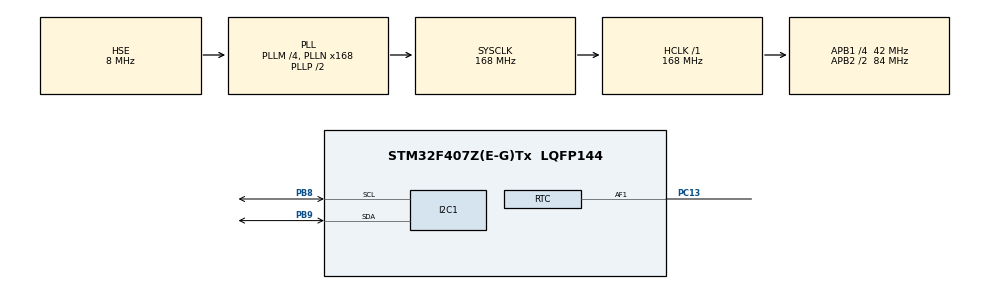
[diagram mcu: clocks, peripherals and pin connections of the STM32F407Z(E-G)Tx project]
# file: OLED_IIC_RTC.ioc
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Mcu.Family=STM32F4
Mcu.Name=STM32F407Z(E-G)Tx
Mcu.Package=LQFP144
NVIC.PriorityGroup=NVIC_PRIORITYGROUP_2
NVIC.RTC_Alarm_IRQn=true\:1\:1\:true\:false\:true\:true\:true\:true
NVIC.RTC_WKUP_IRQn=true\:1\:0\:true\:false\:true\:true\:true\:true
PA13.Mode=Serial_Wire
PA13.Signal=SYS_JTMS-SWDIO
PA14.Mode=Serial_Wire
PA14.Signal=SYS_JTCK-SWCLK
PB8.Mode=I2C
PB8.Signal=I2C1_SCL
PB9.Mode=I2C
PB9.Signal=I2C1_SDA
PC13-ANTI_TAMP.Mode=WakeUpAF1
PC13-ANTI_TAMP.Signal=RTC_AF1
PC14-OSC32_IN.Mode=LSE-External-Oscillator
PC14-OSC32_IN.Signal=RCC_OSC32_IN
PC15-OSC32_OUT.Mode=LSE-External-Oscillator
PC15-OSC32_OUT.Signal=RCC_OSC32_OUT
PH0-OSC_IN.Mode=HSE-External-Oscillator
PH0-OSC_IN.Signal=RCC_OSC_IN
PH1-OSC_OUT.Mode=HSE-External-Oscillator
PH1-OSC_OUT.Signal=RCC_OSC_OUT
ProjectManager.HeapSize=0x200
ProjectManager.StackSize=0x400
ProjectManager.TargetToolchain=STM32CubeIDE
RCC.48MHZClocksFreq_Value=84000000
RCC.AHBFreq_Value=168000000
RCC.APB1CLKDivider=RCC_HCLK_DIV4
RCC.APB1Freq_Value=42000000
RCC.APB1TimFreq_Value=84000000
RCC.APB2CLKDivider=RCC_HCLK_DIV2
RCC.APB2Freq_Value=84000000
RCC.APB2TimFreq_Value=168000000
RCC.CortexFreq_Value=168000000
RCC.HCLKFreq_Value=168000000
RCC.HSE_VALUE=8000000
RCC.HSI_VALUE=16000000
RCC.PLLM=4
RCC.PLLN=168
RCC.PLLSourceVirtual=RCC_PLLSOURCE_HSE
RCC.RCC_RTC_Clock_Source=RCC_RTCCLKSOURCE_LSE
RCC.SYSCLKFreq_VALUE=168000000
RCC.SYSCLKSource=RCC_SYSCLKSOURCE_PLLCLK
RCC.VCOOutputFreq_Value=336000000
RTC.Alarm=RTC_ALARM_A
RTC.AlarmDateWeekDay=3
RTC.AlarmMaskDateWeekDay=RTC_ALARMMASK_DATEWEEKDAY
RTC.AlarmMaskDateWeekDay_B=RTC_ALARMMASK_DATEWEEKDAY
RTC.AlarmMaskHours=RTC_ALARMMASK_HOURS
RTC.AlarmMaskHours_B=RTC_ALARMMASK_HOURS
RTC.AlarmMaskMinutes_B=RTC_ALARMMASK_MINUTES
RTC.Alarm_B=RTC_ALARM_B
RTC.Date=16
RTC.Hours=7
RTC.Hours_A=8
RTC.Hours_B=10
RTC.Minutes=15
RTC.Minutes_A=16
RTC.Minutes_B=20
RTC.Month=RTC_MONTH_MARCH
RTC.OutPutPolarity=RTC_OUTPUT_POLARITY_LOW
RTC.Seconds=10
RTC.Seconds_A=5
RTC.Seconds_B=30
RTC.WakeUpClock=RTC_WAKEUPCLOCK_CK_SPRE_16BITS
RTC.WeekDay=RTC_WEEKDAY_SATURDAY
RTC.Year=19
VP_RTC_VS_RTC_Activate.Mode=RTC_Enabled
VP_RTC_VS_RTC_Alarm_A_Intern.Mode=Alarm A
VP_RTC_VS_RTC_Alarm_B_Intern.Mode=Alarm B
VP_RTC_VS_RTC_Calendar.Mode=RTC_Calendar
board=custom

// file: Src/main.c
/* USER CODE BEGIN Header */
/**
  ******************************************************************************
  * @file           : main.c
  * @brief          : Main program body
  ******************************************************************************
  * @attention
  *
  * Copyright (c) 2022 STMicroelectronics.
  * All rights reserved.
  *
  * This software is licensed under terms that can be found in the LICENSE file
  * in the root directory of this software component.
  * If no LICENSE file comes with this software, it is provided AS-IS.
  *
  ******************************************************************************
  */
/* USER CODE END Header */
#include "main.h"
#include "i2c.h"
#include "rtc.h"
#include "gpio.h"

/* USER CODE BEGIN Includes */
#include "oled.h"
/* USER CODE END Includes */

void SystemClock_Config(void);

/* USER CODE BEGIN 0 */
extern unsigned char BMP1[];
uint8_t t;
/* USER CODE END 0 */

int main(void)
{

  /* MCU Configuration--------------------------------------------------------*/

  /* Reset of all peripherals, Initializes the Flash interface and the Systick. */
  HAL_Init();

  /* Configure the system clock */
  SystemClock_Config();

  /* Initialize all configured peripherals */
  MX_GPIO_Init();
  MX_I2C1_Init();
  MX_RTC_Init();
  /* USER CODE BEGIN 2 */
  OLED_Init();					//初始化OLED
  	OLED_Clear();
//  	OLED_ShowCHinese(0,0,0);
//  	OLED_ShowCHinese(15,0,1);
//  	OLED_ShowCHinese(30,0,2);
//  	HAL_Delay(2000);
//  	OLED_Clear();
//  	OLED_DrawBMP(0,0,128,8,BMP1);
//  	HAL_Delay(2000);
//  	OLED_Clear();
  /* USER CODE END 2 */

  /* Infinite loop */
  /* USER CODE BEGIN WHILE */
  while (1)
  {
//	  uint16_t jj=123;
//		OLED_ShowString(0,0,(uint8_t *)"12345",12);
//		OLED_ShowString(60,0,(uint8_t *)"12345",12);
//	  OLED_ShowNum(0,5,jj,5,12);
    /* USER CODE END WHILE */

  }
}

void SystemClock_Config(void)
{
  RCC_OscInitTypeDef RCC_OscInitStruct = {0};
  RCC_ClkInitTypeDef RCC_ClkInitStruct = {0};

  /** Configure the main internal regulator output voltage
  */
  __HAL_RCC_PWR_CLK_ENABLE();
  __HAL_PWR_VOLTAGESCALING_CONFIG(PWR_REGULATOR_VOLTAGE_SCALE1);

  /** Initializes the RCC Oscillators according to the specified parameters
  * in the RCC_OscInitTypeDef structure.
  */
  RCC_OscInitStruct.OscillatorType = RCC_OSCILLATORTYPE_HSE|RCC_OSCILLATORTYPE_LSE;
  RCC_OscInitStruct.HSEState = RCC_HSE_ON;
  RCC_OscInitStruct.LSEState = RCC_LSE_ON;
  RCC_OscInitStruct.PLL.PLLState = RCC_PLL_ON;
  RCC_OscInitStruct.PLL.PLLSource = RCC_PLLSOURCE_HSE;
  RCC_OscInitStruct.PLL.PLLM = 4;
  RCC_OscInitStruct.PLL.PLLN = 168;
  RCC_OscInitStruct.PLL.PLLP = RCC_PLLP_DIV2;
  RCC_OscInitStruct.PLL.PLLQ = 4;
  if (HAL_RCC_OscConfig(&RCC_OscInitStruct) != HAL_OK)
  {
    Error_Handler();
  }

  /** Initializes the CPU, AHB and APB buses clocks
  */
  RCC_ClkInitStruct.ClockType = RCC_CLOCKTYPE_HCLK|RCC_CLOCKTYPE_SYSCLK
                              |RCC_CLOCKTYPE_PCLK1|RCC_CLOCKTYPE_PCLK2;
  RCC_ClkInitStruct.SYSCLKSource = RCC_SYSCLKSOURCE_PLLCLK;
  RCC_ClkInitStruct.AHBCLKDivider = RCC_SYSCLK_DIV1;
  RCC_ClkInitStruct.APB1CLKDivider = RCC_HCLK_DIV4;
  RCC_ClkInitStruct.APB2CLKDivider = RCC_HCLK_DIV2;

  if (HAL_RCC_ClockConfig(&RCC_ClkInitStruct, FLASH_LATENCY_5) != HAL_OK)
  {
    Error_Handler();
  }
}

void Error_Handler(void)
{
  __disable_irq();
  while (1)
  {
  }
}
